# PY32F001xx register map
Vendor: Puya; Series: PY32F0; File version: 1.0.0
Arm 32-bit Cortex-M0+ Microcontroller based device, CPU clock up to 48 MHz.
CPU: CM0+ r0p1, little endian, no MPU, no FPU, 4 interrupt priority bits
Registers are 32-bit, read-write, reset 0x0 unless marked. A register's access mark holds for its fields unless they carry their own. Offsets are from the block's base; lines under a group give offsets from that group; [hi:lo] are bit positions; {n}, {i} and the like mark numbered series; 'fields as' and 'values as' point back to an identical list; <NAME> marks a mode.

## Memory map
0x40002000 TIM14 size 0x400 — General purpose timer
0x40003000 IWDG size 0x400 — Independent watchdog
0x40007000 PWR size 0x400 — Power control
0x40007C00 LPTIM1 size 0x400 — Low power timer
0x40010000 SYSCFG size 0x30 — System configuration controller
0x40010200 COMP1 size 0x10 — Comparator 1
0x40010210 COMP2 size 0x10 — Comparator2
0x40012C00 TIM1 size 0x400 — Advanced timer
0x40015800 DBGMCU size 0x400 — Debug support
0x40021000 RCC size 0x400 — Reset and clock control
0x40021800 EXTI size 0x400 — External interrupt/event controller
0x40022000 FLASH size 0x400
0x40023000 CRC size 0x400 — CRC calculation unit
0x50000000 GPIOA size 0x400 — General-purpose I/Os
0x50000400 GPIOB size 0x400 — General-purpose I/Os
0x50000800 GPIOC size 0x400

## Interrupts
3 FLASH — FLASH global Interrupt
4 RCC — RCC global Interrupt
5 EXTI0_1 (EXTI) — EXTI Line 0 and 1 Interrupt
6 EXTI2_3 (EXTI) — EXTI Line 2 and 3 Interrupt
7 EXTI4_15 (EXTI) — EXTI Line 4 to 15 Interrupt
12 ADC_COMP (COMP1, COMP2) — ADC and COMP Interrupts
13 TIM1_BRK_UP_TRG_COM (TIM1) — TIM1 Break, Update, Trigger and Commutation Interrupt
14 TIM1_CC (TIM1) — TIM1 Capture Compare Interrupt
17 LPTIM1_DAC (LPTIM1) — LPTIM1, DAC global Interrupts
19 TIM14 — TIM14 global Interrupt

## COMP1 — Comparator 1
Base 0x40010200
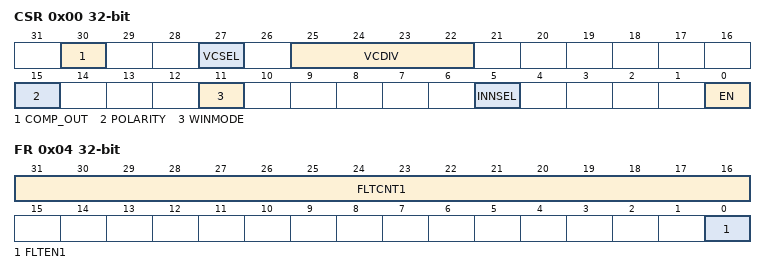
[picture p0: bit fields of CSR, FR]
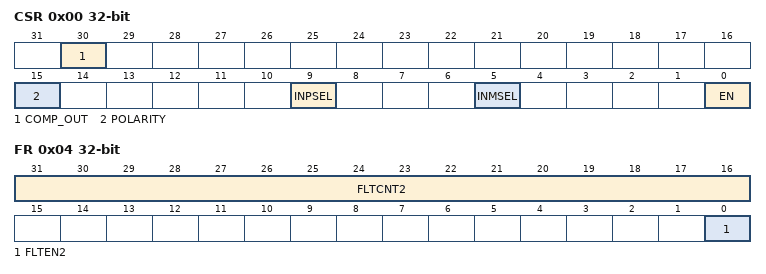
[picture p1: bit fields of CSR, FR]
0x00 CSR — COMP control and status register
  [30] COMP_OUT — Comparator output status
  [27] VCSEL
  [25:22] VCDIV
  [15] POLARITY — Comparator polarity selector
  [11] WINMODE — Comparator non-inverting input selector for window mode
  [5] INNSEL
  [0] EN — COMP enable bit
0x04 FR — Comparator Filter register
  [31:16] FLTCNT1 — Comparator filter and counter
  [0] FLTEN1 — Filter enable bit

## COMP2 — Comparator2
Base 0x40010210
0x00 CSR — COMP control and status register
  [30] COMP_OUT — Comparator output status
  [15] POLARITY — Comparator polarity selector
  [9] INPSEL — Comparator signal selector for non-inverting input
  [5] INMSEL — Comparator signal selector for inverting input INM
  [0] EN — COMP enable bit
0x04 FR — Comparator Filter register
  [31:16] FLTCNT2 — Comparator filter and counter
  [0] FLTEN2 — Filter enable bit

## CRC — CRC calculation unit
Base 0x40023000
0x00 DR reset 0xFFFFFFFF — Data register
  [31:0] DR — Data Register
0x04 IDR — Independent Data register
  [7:0] IDR
0x08 CR wo — Control register
  [0] RESET — Reset bit

## DBGMCU — Debug support
Base 0x40015800
0x00 IDCODE ro — MCU Device ID Code Register
  [31:0] REV_ID
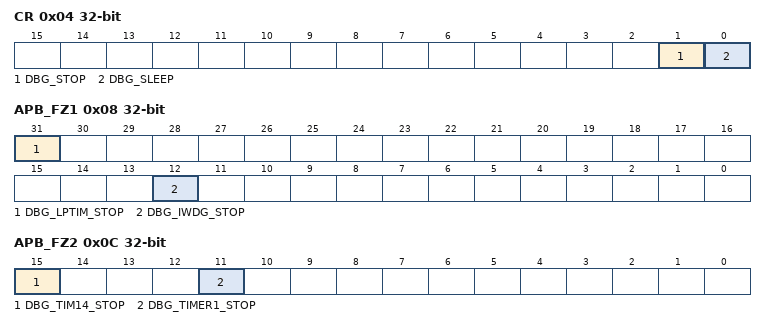
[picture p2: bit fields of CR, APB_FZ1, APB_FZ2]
0x04 CR — Debug MCU Configuration Register
  [1] DBG_STOP — Debug Stop Mode
  [0] DBG_SLEEP — Debug Sleep Mode
0x08 APB_FZ1 — APB Freeze Register1
  [31] DBG_LPTIM_STOP — Debug LPTIM stopped when Core ishalted
  [12] DBG_IWDG_STOP — Debug Independent Wachdog stopped whenCore is halted
0x0C APB_FZ2 — APB Freeze Register2
  [15] DBG_TIM14_STOP — Debug TIM 14 stopped whenCore is halted
  [11] DBG_TIMER1_STOP — Debug Timer 1 stopped when Core ishalted

## EXTI — External interrupt/event controller
Base 0x40021800
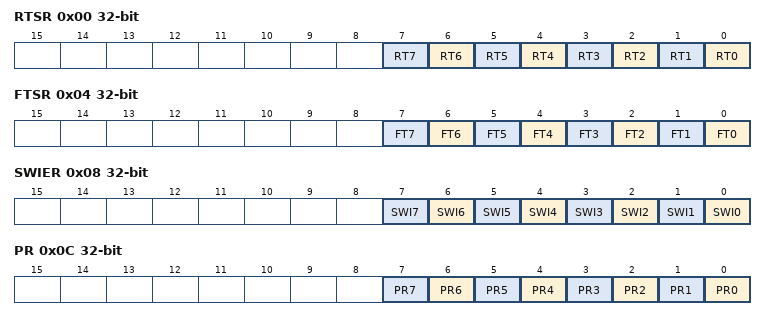
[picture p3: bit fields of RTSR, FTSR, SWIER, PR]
0x00 RTSR — EXTI rising trigger selection register
  [n] RT{n} (n=0..7) — Rising trigger event configuration bit of Configurable Event input
0x04 FTSR — EXTI falling trigger selection register
  [n] FT{n} (n=0..7) — Falling trigger event configuration bit of Configurable Event input
0x08 SWIER — EXTI software interrupt event register
  [n] SWI{n} (n=0..7) — Rising trigger event configuration bit of Configurable Event input
0x0C PR — EXTI pending register
  [n] PR{n} (n=0..7) — configurable event inputs x rising edge Pending bit.
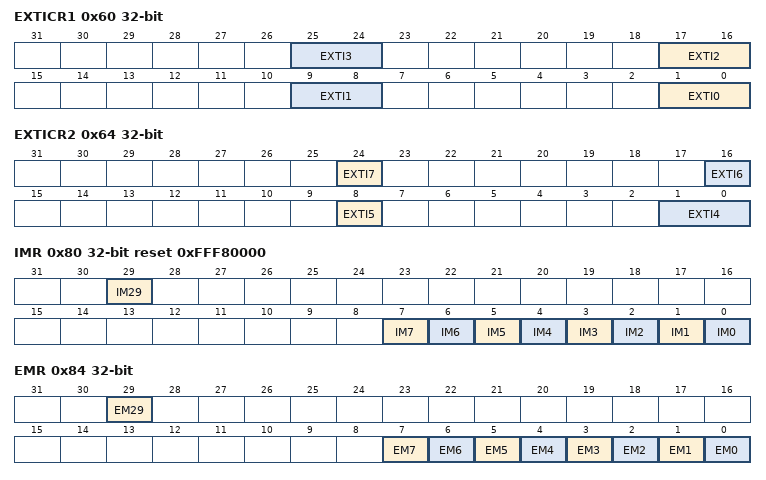
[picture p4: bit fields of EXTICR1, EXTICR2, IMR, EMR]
0x60 EXTICR1 — EXTI external interrupt selection register
  [8n+1:8n] EXTI{n} (n=0..3) — GPIO port selection
0x64 EXTICR2 — EXTI external interrupt selection register
  [24] EXTI7 — GPIO port selection
  [16] EXTI6 — GPIO port selection
  [8] EXTI5 — GPIO port selection
  [1:0] EXTI4 — GPIO port selection
0x80 IMR reset 0xFFF80000 — EXTI CPU wakeup with interrupt mask register
  [29] IM29 — CPU wakeup with interrupt mask on event input
  [n] IM{n} (n=0..7) — CPU wakeup with interrupt mask on event input
0x84 EMR — EXTI CPU wakeup with event mask register
  [29] EM29 — CPU wakeup with event mask on event input
  [n] EM{n} (n=0..7) — CPU wakeup with event mask on event input
